# STM32N657xx register map
File version: 1.0
Registers are 32-bit, read-write, reset 0x0 unless marked. A register's access mark holds for its fields unless they carry their own. Offsets are from the block's base; [hi:lo] are bit positions; {n}, {i} and the like mark numbered series; 'fields as' and 'values as' point back to an identical list.

## RCC (part 1 of 2) — Reset and Clock Control
Base 0x46028000
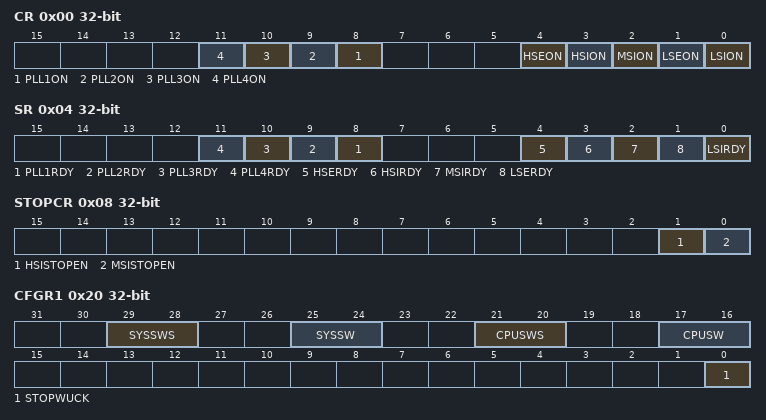
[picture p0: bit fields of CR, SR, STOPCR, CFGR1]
0x00 CR — RCC control register
  [n+7] PLL{n}ON (n=1..4) — PLL{n} enable
  [4] HSEON — HSE oscillator enable
  [3] HSION — HSI oscillator enable
  [2] MSION — MSI oscillator enable
  [1] LSEON — LSE oscillator enable
  [0] LSION — LSI oscillator enable
0x04 SR — RCC status register
  [n+7] PLL{n}RDY (n=1..4) — PLL{n} clock ready flag
  [4] HSERDY — HSE clock ready flag
  [3] HSIRDY — HSI clock ready flag
  [2] MSIRDY — MSI clock ready flag
  [1] LSERDY — LSE clock ready flag
  [0] LSIRDY — LSI clock ready flag
0x08 STOPCR — RCC Stop mode control register
  [1] HSISTOPEN — HSI oscillator enable
  [0] MSISTOPEN — MSI oscillator enable
0x20 CFGR1 — RCC configuration register 1
  [29:28] SYSSWS — System clock switch status
    0=HSI (HSI used as system bus clocks); 1=MSI (MSI used as system bus clocks); 2=HSE (HSE used as system bus clocks); 3=IC2_IC6_IC11 (IC2/IC6/IC11 used as system bus clocks)
  [25:24] SYSSW — System clock switch selection
    0=HSI (Select HSI as system bus clocks); 1=MSI (Select MSI as system bus clocks); 2=HSE (Select HSE as system bus clocks); 3=IC2_IC6_IC11 (Select IC2/IC6/IC11 as system bus clocks)
  [21:20] CPUSWS — CPU clock switch status
    0=HSI (HSI used as CPU clock); 1=MSI (MSI used as CPU clock); 2=HSE (HSE used as CPU clock); 3=IC1 (IC1 used as CPU clock)
  [17:16] CPUSW — CPU clock switch selection
    0=HSI (Select HSI as CPU clock); 1=MSI (Select MSI as CPU clock); 2=HSE (Select HSE as CPU clock); 3=IC1 (Select IC1 as CPU clock)
  [0] STOPWUCK — System clock selection after a wake up from system stop
    0=HSI; 1=MSI
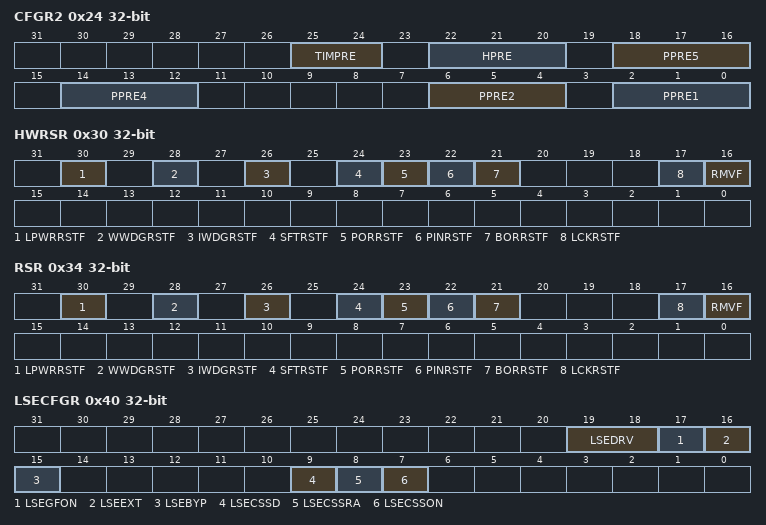
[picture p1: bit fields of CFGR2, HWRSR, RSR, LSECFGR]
0x24 CFGR2 — RCC configuration register 2
  [25:24] TIMPRE — Timer clock prescaler selection
  [22:20] HPRE — AHB clock prescaler
    0=DIV_1; 1=DIV_2; 2=DIV_4; 3=DIV_8; 4=DIV_16; 5=DIV_32; 6=DIV_64; 7=DIV_128
  [18:16] PPRE5 — CPU domain APB5 prescaler
    values as HPRE
  [14:12] PPRE4 — CPU domain APB4 prescaler
    values as HPRE
  [6:4] PPRE2 — CPU domain APB2 prescaler
    values as HPRE
  [2:0] PPRE1 — CPU domain APB1 prescaler
    values as HPRE
0x2C BDCR — RCC backup domain protection register
  [31] VSWRST — Vswitch (VSW) domain software reset
0x30 HWRSR — RCC reset status register for hardware
  [30] LPWRRSTF — Illegal Stop or Standby flag
  [28] WWDGRSTF — Window watchdog reset flag
  [26] IWDGRSTF — Independent watchdog reset flag
  [24] SFTRSTF — Software system reset flag
  [23] PORRSTF — POR/PDR reset flag
  [22] PINRSTF — Pin reset flag (NRST)
  [21] BORRSTF — BOR reset flag
  [17] LCKRSTF — CPU lockup reset flag
  [16] RMVF — Remove reset flag
0x34 RSR — RCC reset register
  fields as HWRSR
0x40 LSECFGR — RCC LSE configuration register
  [19:18] LSEDRV — LSE oscillator driving capability
    0=LOW; 2=MEDIUMLOW; 1=MEDIUMHIGH; 3=HIGH
  [17] LSEGFON — LSE clock glitch filter enable
  [16] LSEEXT — LSE clock type in bypass mode
  [15] LSEBYP — LSE clock bypass
  [9] LSECSSD — LSE clock security system (CSS) failure detection
  [8] LSECSSRA — LSE clock security system (CSS) rearm function
  [7] LSECSSON — LSE clock security system (CSS) enable
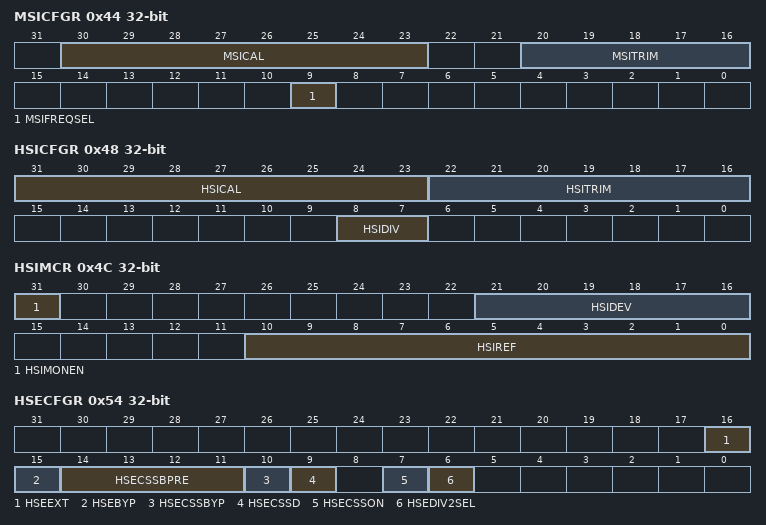
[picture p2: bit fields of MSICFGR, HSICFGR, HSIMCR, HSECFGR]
0x44 MSICFGR — RCC MSI configuration register
  [30:23] MSICAL — MSI clock calibration
  [20:16] MSITRIM — MSI clock trimming
  [9] MSIFREQSEL — MSI oscillator frequency selection
    0=FREQ_4MHZ; 1=FREQ_16MHZ
0x48 HSICFGR — RCC HSI configuration register
  [31:23] HSICAL — HSI clock calibration
  [22:16] HSITRIM — HSI clock trimming
  [8:7] HSIDIV — HSI clock divider
    0=DIV_1; 1=DIV_2; 2=DIV_4; 3=DIV_8
0x4C HSIMCR — RCC HSI Monitor control register
  [31] HSIMONEN — HSI clock period monitor enable
  [21:16] HSIDEV — HSI clock count deviation value
  [10:0] HSIREF — HSI clock-cycle counter reference value
0x50 HSIMSR — RCC HSI Monitor status register
  [10:0] HSIVAL — HSI clock-cycle counter measured value
0x54 HSECFGR — RCC HSE configuration register
  [16] HSEEXT — HSE clock type in bypass mode
  [15] HSEBYP — HSE clock bypass
  [14:11] HSECSSBPRE — HSE CSS bypass divider
  [10] HSECSSBYP — HSE CSS bypass enable
  [9] HSECSSD — HSE CSS failure detection
  [7] HSECSSON — HSE CSS enable
  [6] HSEDIV2SEL — HSE div2 clock source select
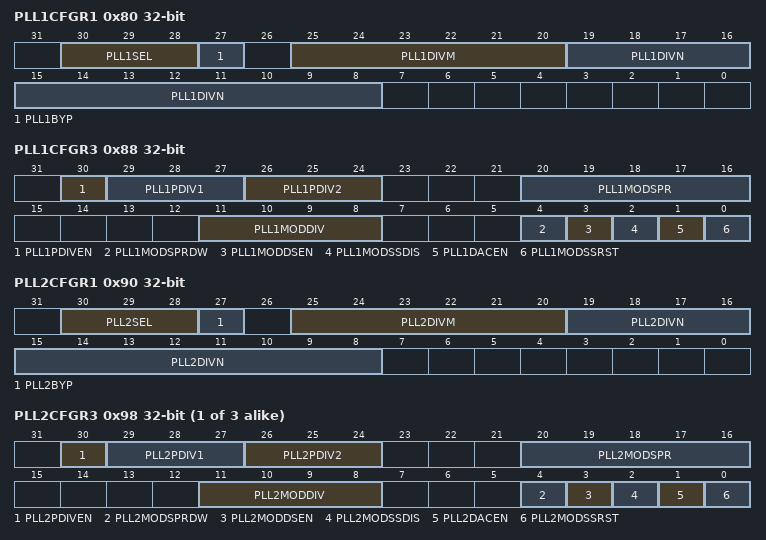
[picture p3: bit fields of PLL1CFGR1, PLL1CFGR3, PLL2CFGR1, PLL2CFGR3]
0x80 PLL1CFGR1 — RCC PLL1 configuration register 1
  [30:28] PLL1SEL — PLL1 source selection of the reference clock
    0=HSI; 1=MSI; 2=HSE; 3=I2S_CKIN
  [27] PLL1BYP — PLL1 bypass
  [25:20] PLL1DIVM — PLL1 reference input clock divide frequency ratio
  [19:8] PLL1DIVN — PLL1 integer part for the VCO multiplication factor
{0x74+0x10*i} PLL{i}CFGR2 (i=1..4) — RCC PLL{i} configuration register 2
  [23:0] PLL{i}DIVNFRAC — PLL{i} fractional part of the VCO multiplication factor
0x88 PLL1CFGR3 — RCC PLL1 configuration register 3
  [30] PLL1PDIVEN — PLL1 post divider POSTDIV1, POSTDIV2, and PLL clock output enable
  [29:27] PLL1PDIV1 — PLL1 VCO frequency divider level 1
  [26:24] PLL1PDIV2 — PLL1 VCO frequency divider level 2
  [20:16] PLL1MODSPR — PLL1 modulation spread depth adjustment
  [11:8] PLL1MODDIV — PLL1 modulation division frequency adjustment
  [4] PLL1MODSPRDW — PLL1 modulation spread spectrum down
  [3] PLL1MODDSEN — PLL1 modulation spread spectrum (and fractional divide) enable
  [2] PLL1MODSSDIS — PLL1 modulation spread spectrum disable
  [1] PLL1DACEN — PLL1 noise canceling DAC enable in fractional mode
  [0] PLL1MODSSRST — PLL1 modulation spread spectrum reset
0x90 PLL2CFGR1 — RCC PLL2 configuration register 1
  [30:28] PLL2SEL — PLL2 source selection of the reference clock
    0=HSI; 1=MSI; 2=HSE; 3=I2S_CKIN
  [27] PLL2BYP — PLL2 bypass
  [25:20] PLL2DIVM — PLL2 reference input clock divide frequency ratio
  [19:8] PLL2DIVN — PLL2 integer part for the VCO multiplication factor
{0x78+0x10*i} PLL{i}CFGR3 (i=2..4) — RCC PLL{i} configuration register 3
  [30] PLL{i}PDIVEN — PLL{i} post divider POSTDIV1, POSTDIV2, and PLL clock output enable
  [29:27] PLL{i}PDIV1 — PLL{i} VCO frequency divider level 1
  [26:24] PLL{i}PDIV2 — PLL{i} VCO frequency divider level 2
  [20:16] PLL{i}MODSPR — PLL{i} modulation spread depth adjustment
  [11:8] PLL{i}MODDIV — PLL{i} modulation division frequency adjustment
  [4] PLL{i}MODSPRDW — PLL{i} modulation down spread
  [3] PLL{i}MODDSEN — PLL{i} modulation spread spectrum (and fractional divide) enable
  [2] PLL{i}MODSSDIS — PLL{i} modulation spread spectrum disable
  [1] PLL{i}DACEN — PLL{i} noise canceling DAC enable in fractional mode
  [0] PLL{i}MODSSRST — PLL{i} modulation spread spectrum reset
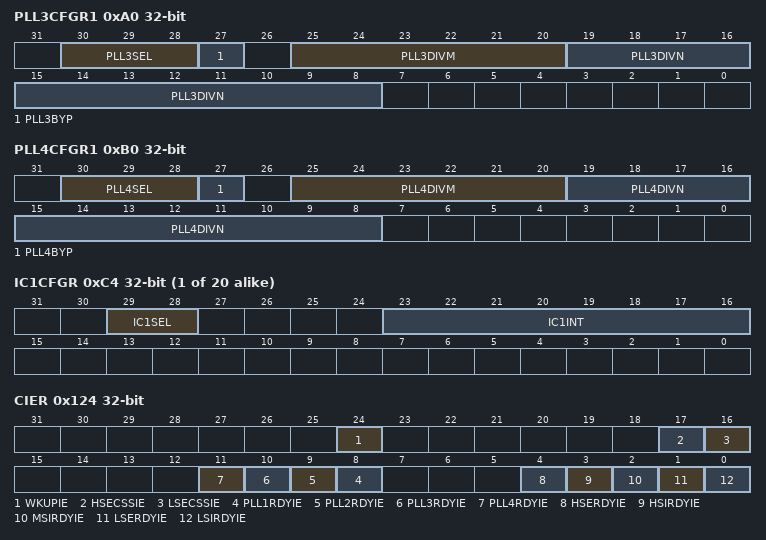
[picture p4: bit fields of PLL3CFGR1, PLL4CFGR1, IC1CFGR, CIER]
0xA0 PLL3CFGR1 — RCC PLL3 configuration register 1
  [30:28] PLL3SEL — PLL3 source selection of the reference clock
    0=HSI; 1=MSI; 2=HSE; 3=I2S_CKIN
  [27] PLL3BYP — PLL3 bypass
  [25:20] PLL3DIVM — PLL3 reference input clock divide frequency ratio
  [19:8] PLL3DIVN — PLL3 Integer part for the VCO multiplication factor
0xB0 PLL4CFGR1 — RCC PLL4 configuration register 1
  [30:28] PLL4SEL — PLL4 source selection of the reference clock
    0=HSI; 1=MSI; 2=HSE; 3=I2S_CKIN
  [27] PLL4BYP — PLL4 bypass
  [25:20] PLL4DIVM — PLL4 reference input clock divide frequency ratio
  [19:8] PLL4DIVN — PLL4 integer part for the VCO multiplication factor
{0xC0+4i} IC{i}CFGR (i=1..20) — RCC IC{i} configuration register
  [29:28] IC{i}SEL — Divider IC{i} source selection
    {v}=PLL{v+1} (v=0..3)
  [23:16] IC{i}INT — Divider IC{i} integer division factor
0x124 CIER — RCC clock-source interrupt enable register
  [24] WKUPIE — CPU wake-up from Stop interrupt enable
  [17] HSECSSIE — HSE CSS interrupt enable
  [16] LSECSSIE — LSE CSS interrupt enable
  [n+7] PLL{n}RDYIE (n=1..4) — PLL{n} ready interrupt enable
  [4] HSERDYIE — HSE ready interrupt enable
  [3] HSIRDYIE — HSI ready interrupt enable
  [2] MSIRDYIE — MSI ready interrupt enable
  [1] LSERDYIE — LSE ready interrupt enable
  [0] LSIRDYIE — LSI ready interrupt enable
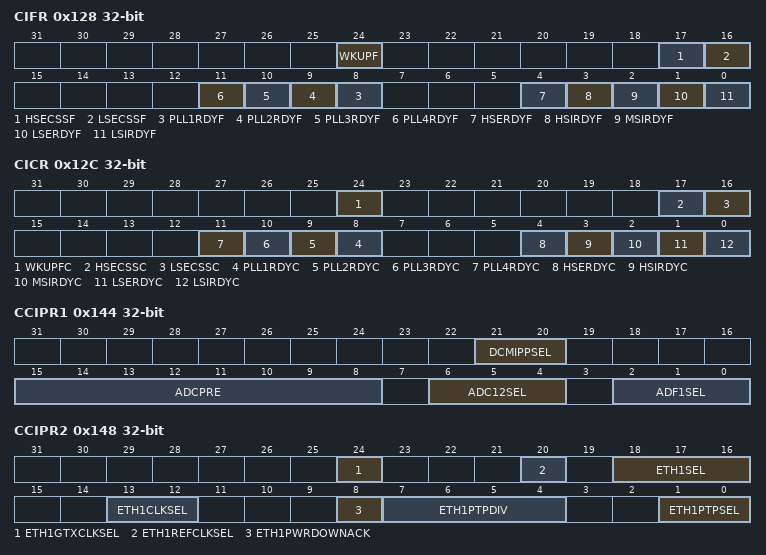
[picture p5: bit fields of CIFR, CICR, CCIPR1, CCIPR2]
0x128 CIFR — RCC clock-source interrupt flag register
  [24] WKUPF — CPU wake-up from Stop interrupt flag
  [17] HSECSSF — HSE ready interrupt flag
  [16] LSECSSF — LSE ready interrupt flag
  [n+7] PLL{n}RDYF (n=1..4) — PLL{n} ready interrupt flag
  [4] HSERDYF — HSE ready interrupt flag
  [3] HSIRDYF — HSI ready interrupt flag
  [2] MSIRDYF — MSI ready interrupt flag
  [1] LSERDYF — LSE ready interrupt flag
  [0] LSIRDYF — LSI ready interrupt flag
0x12C CICR — RCC clock-source interrupt clear register
  [24] WKUPFC — CPU wake-up ready interrupt clear
  [17] HSECSSC — HSE ready interrupt clear
  [16] LSECSSC — LSE ready interrupt clear
  [n+7] PLL{n}RDYC (n=1..4) — PLL{n} ready interrupt clear
  [4] HSERDYC — HSE ready interrupt clear
  [3] HSIRDYC — HSI ready interrupt clear
  [2] MSIRDYC — MSI ready interrupt clear
  [1] LSERDYC — LSE ready interrupt clear
  [0] LSIRDYC — LSI ready interrupt clear
0x144 CCIPR1 — RCC clock configuration for independent peripheral register 1
  [21:20] DCMIPPSEL — Source selection for the DCMIPP kernel clock
    0=PCLK5; 1=CLKP; 2=IC17; 3=HSI
  [15:8] ADCPRE — ADC12 Bus Slave clock divider selection (for clock ck_icn_s_vencram)
  [6:4] ADC12SEL — Source selection for the ADC12 kernel clock
    0=HCLK; 1=CLKP; 2=IC7; 3=IC8; 4=MSI; 5=HSI; 6=I2S_CKIN; 7=TIMG
  [2:0] ADF1SEL — Source selection for the ADF1 kernel clock
    values as ADC12SEL
0x148 CCIPR2 — RCC clock configuration for independent peripheral register 2
  [24] ETH1GTXCLKSEL — Set and reset by software
    0=EXT; 1=INT
  [20] ETH1REFCLKSEL — Set and reset by software
    0=EXT; 1=INT
  [18:16] ETH1SEL — Set and reset by software
    0=MII; 1=RGMII; 4=RMII; 7=IF
  [13:12] ETH1CLKSEL — Source selection for the ETH1 kernel clock
    0=HCLK; 1=CLKP; 2=IC12; 3=HSE
  [8] ETH1PWRDOWNACK — Set and reset by software
  [7:4] ETH1PTPDIV — ETH1 Kernel clock divider selection (for clock ck_ker_eth1ptp)
    {v}=DIV_{v+1} (v=0..15)
  [1:0] ETH1PTPSEL — Source selection for the ETH1 kernel clock
    0=HCLK; 1=CLKP; 2=IC13; 3=HSE
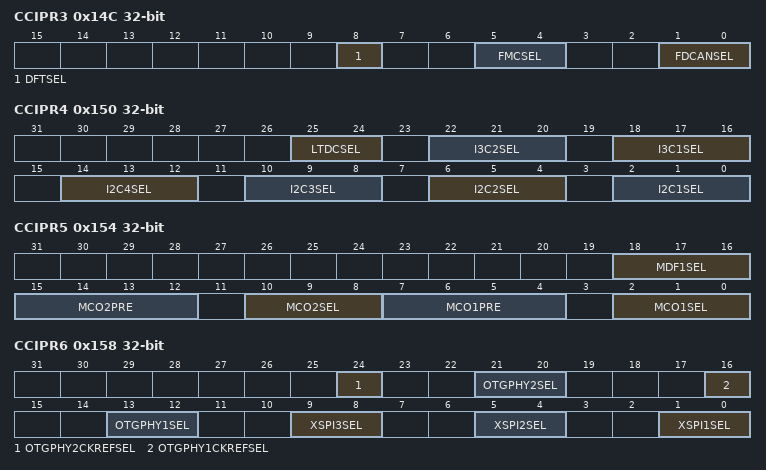
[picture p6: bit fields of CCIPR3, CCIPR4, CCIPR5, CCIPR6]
0x14C CCIPR3 — RCC clock configuration for independent peripheral register 3
  [8] DFTSEL — Source selection for the DFT kernel clock
  [5:4] FMCSEL — Source selection for the FMC kernel clock
    0=HCLK; 1=CLKP; 2=IC3; 3=IC4
  [1:0] FDCANSEL — Source selection for the FDCAN kernel clock
    0=PCLK1; 1=CLKP; 2=IC19; 3=HSE
0x150 CCIPR4 — RCC clock configuration for independent peripheral register 4
  [25:24] LTDCSEL — Source selection for the LTDC kernel clock
    0=PCLK5; 1=CLKP; 2=IC16; 3=HSI
  [22:20] I3C2SEL — Source selection for the I3C2 kernel clock
  [18:16] I3C1SEL — Source selection for the I3C1 kernel clock
  [4n-2:4n-4] I2C{n}SEL (n=1..4) — Source selection for the I2C{n} kernel clock
0x154 CCIPR5 — RCC clock configuration for independent peripheral register 5
  [18:16] MDF1SEL — Source selection for the MDF1 kernel clock
    values as CCIPR1.ADC12SEL
  [15:12] MCO2PRE — MCO2 Kernel clock divider selection (for clock MCO2)
  [10:8] MCO2SEL — Source selection for the MCO2 kernel clock
  [7:4] MCO1PRE — MCO1 Kernel clock divider selection (for clock MCO1)
  [2:0] MCO1SEL — Source selection for the MCO1 kernel clock
0x158 CCIPR6 — RCC clock configuration for independent peripheral register 6
  [24] OTGPHY2CKREFSEL — Set and reset by software
  [21:20] OTGPHY2SEL — Source selection for the OTGPHY2 kernel clock
  [16] OTGPHY1CKREFSEL — Set and reset by software
  [13:12] OTGPHY1SEL — Source selection for the OTGPHY1 kernel clock
  [9:8] XSPI3SEL — Source selection for the XSPI3 kernel clock
  [5:4] XSPI2SEL — Source selection for the XSPI2 kernel clock
  [1:0] XSPI1SEL — Source selection for the XSPI1 kernel clock
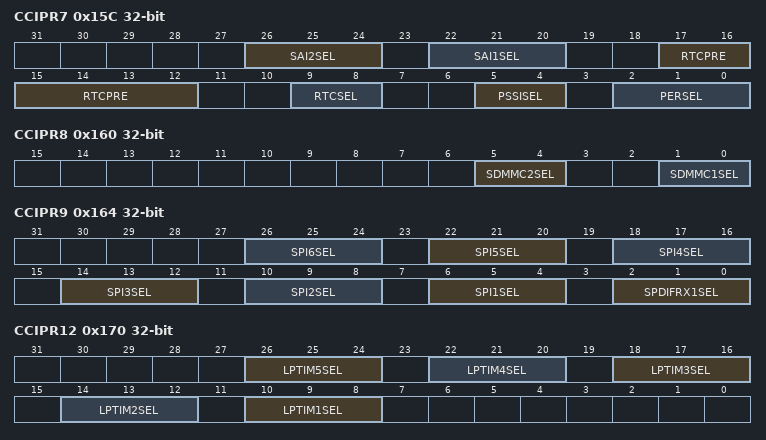
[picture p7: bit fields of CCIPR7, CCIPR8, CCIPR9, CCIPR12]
0x15C CCIPR7 — RCC clock configuration for independent peripheral register 7
  [26:24] SAI2SEL — Source selection for the SAI2 kernel clock
  [22:20] SAI1SEL — Source selection for the SAI1 kernel clock
  [17:12] RTCPRE — RTC OSC clock divider selection (for clock hse_ck)
    0=DIV_1; 1=DIV_4; 2=DIV_9; 3=DIV_16; 4=DIV_25; 5=DIV_36; 6=DIV_49; 7=DIV_64; 8=DIV_81; 9=DIV_100; 10=DIV_121; 11=DIV_144; 12=DIV_169; 13=DIV_196; 14=DIV_225; 15=DIV_256; 16=DIV_289; 17=DIV_324; 18=DIV_361; 19=DIV_400; 20=DIV_441; 21=DIV_484; 22=DIV_529; 23=DIV_576; 24=DIV_625; 25=DIV_676; 26=DIV_729; 27=DIV_784; 28=DIV_841; 29=DIV_900; 30=DIV_961; 31=DIV_1024; 32=DIV_1089; 33=DIV_1156; 34=DIV_1225; 35=DIV_1296; 36=DIV_1369; 37=DIV_1444; 38=DIV_1521; 39=DIV_1600; 40=DIV_1681; 41=DIV_1764; 42=DIV_1849; 43=DIV_1936; 44=DIV_2025; 45=DIV_2116; 46=DIV_2209; 47=DIV_2304; 48=DIV_2401; 49=DIV_2500; 50=DIV_2601; 51=DIV_2704; 52=DIV_2809; 53=DIV_2916; 54=DIV_3025; 55=DIV_3136; 56=DIV_3249; 57=DIV_3364; 58=DIV_3481; 59=DIV_3600; 60=DIV_3721; 61=DIV_3844; 62=DIV_3969; 63=DIV_4096
  [9:8] RTCSEL — Source selection for the RTC kernel clock
    0=NONE; 1=LSE; 2=LSI; 3=HSE
  [5:4] PSSISEL — Source selection for the PSSI kernel clock
    0=HCLK; 1=CLKP; 2=IC20; 3=HSI
  [2:0] PERSEL — Source selection for the PER kernel clock
    0=HSI; 1=MSI; 2=HSE; 3=IC19; 4=IC5; 5=IC10; 6=IC15; 7=IC20
0x160 CCIPR8 — RCC clock configuration for independent peripheral register 8
  [5:4] SDMMC2SEL — Source selection for the SDMMC2 kernel clock
  [1:0] SDMMC1SEL — Source selection for the SDMMC1 kernel clock
0x164 CCIPR9 — RCC clock configuration for independent peripheral register 9
  [4n+2:4n] SPI{n}SEL (n=1..6) — Source selection for the SPI{n} kernel clock
  [2:0] SPDIFRX1SEL — Source selection for the SPDIFRX1 kernel clock
    0=PCLK1; 1=CLKP; 2=IC7; 3=IC8; 4=MSI; 5=HSI; 6=I2S_CKIN; 7=CLKSOURCE
0x170 CCIPR12 — RCC clock configuration for independent peripheral register 12
  [4n+6:4n+4] LPTIM{n}SEL (n=1..5) — Source selection for the LPTIM{n} kernel clock
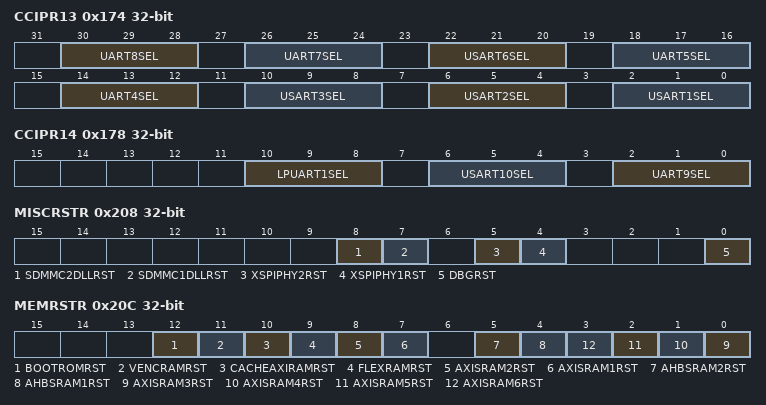
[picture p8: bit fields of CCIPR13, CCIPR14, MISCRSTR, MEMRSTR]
0x174 CCIPR13 — RCC clock configuration for independent peripheral register 13
  [30:28] UART8SEL — Source selection for the UART8 kernel clock
  [26:24] UART7SEL — Source selection for the UART7 kernel clock
  [22:20] USART6SEL — Source selection for the USART6 kernel clock
  [18:16] UART5SEL — Source selection for the UART5 kernel clock
  [14:12] UART4SEL — Source selection for the UART4 kernel clock
  [10:8] USART3SEL — Source selection for the USART3 kernel clock
  [6:4] USART2SEL — Source selection for the USART2 kernel clock
  [2:0] USART1SEL — Source selection for the USART1 kernel clock
0x178 CCIPR14 — RCC clock configuration for independent peripheral register 14
  [10:8] LPUART1SEL — Source selection for the LPUART1 kernel clock
    0=PCLK4; 1=CLKP; 2=IC9; 3=IC14; 4=LSE; 5=MSI; 6=HSI; 7=CLKSOURCE
  [6:4] USART10SEL — Source selection for the USART10 kernel clock
  [2:0] UART9SEL — Source selection for the UART9 kernel clock
0x208 MISCRSTR — RCC miscellaneous configurations reset register
  [8] SDMMC2DLLRST — SDMMC2DLL reset
  [7] SDMMC1DLLRST — SDMMC1DLL reset
  [5] XSPIPHY2RST — XSPIPHY2 reset
  [4] XSPIPHY1RST — XSPIPHY1 reset
  [0] DBGRST — DBG reset
0x20C MEMRSTR — RCC embedded memories reset register
  [12] BOOTROMRST — Boot ROM reset
  [11] VENCRAMRST — VENCRAM reset
  [10] CACHEAXIRAMRST — CACHEAXIRAM reset
  [9] FLEXRAMRST — FLEXRAM reset
  [8] AXISRAM2RST — AXISRAM2 reset
  [7] AXISRAM1RST — AXISRAM1 reset
  [5] AHBSRAM2RST — AHBSRAM2 reset
  [4] AHBSRAM1RST — AHBSRAM1 reset
  [n-3] AXISRAM{n}RST (n=3..6) — AXISRAM{n} reset
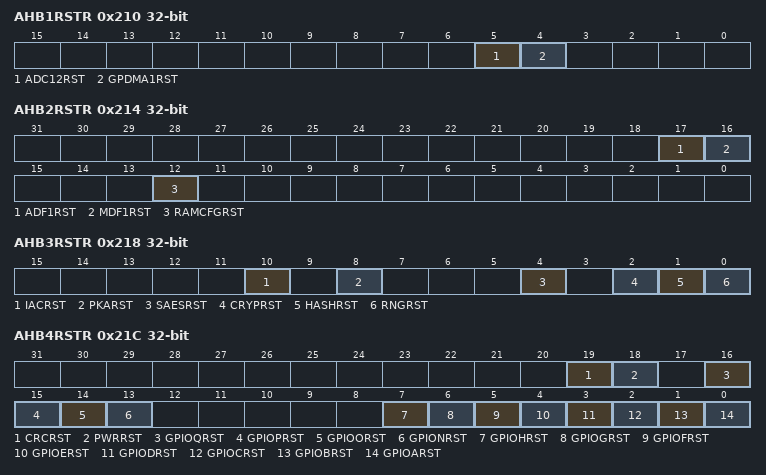
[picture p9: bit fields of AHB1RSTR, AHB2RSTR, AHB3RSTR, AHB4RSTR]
0x210 AHB1RSTR — RCC AHB1 reset register
  [5] ADC12RST — ADC12 reset
  [4] GPDMA1RST — GPDMA1 reset
0x214 AHB2RSTR — RCC AHB2 reset register
  [17] ADF1RST — ADF1 reset
  [16] MDF1RST — MDF1 reset
  [12] RAMCFGRST — RAMCFG reset
0x218 AHB3RSTR — RCC AHB3 reset register
  [10] IACRST — IAC reset
  [8] PKARST — PKA reset
  [4] SAESRST — SAES reset
  [2] CRYPRST — CRYP reset
  [1] HASHRST — HASH reset
  [0] RNGRST — RNG reset
0x21C AHB4RSTR — RCC AHB4 reset register
  [19] CRCRST — CRC reset
  [18] PWRRST — PWR reset
  [16] GPIOQRST — GPIO Q reset
  [15] GPIOPRST — GPIO P reset
  [14] GPIOORST — GPIO O reset
  [13] GPIONRST — GPIO N reset
  [7] GPIOHRST — GPIO H reset
  [6] GPIOGRST — GPIO G reset
  [5] GPIOFRST — GPIO F reset
  [4] GPIOERST — GPIO E reset
  [3] GPIODRST — GPIO D reset
  [2] GPIOCRST — GPIO C reset
  [1] GPIOBRST — GPIO B reset
  [0] GPIOARST — GPIO A reset
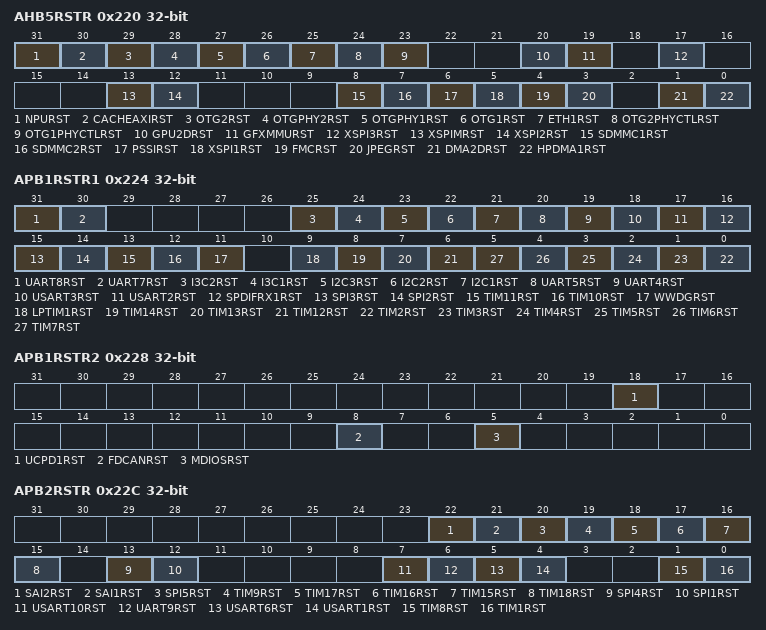
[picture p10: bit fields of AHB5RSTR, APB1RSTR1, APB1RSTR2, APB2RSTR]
0x220 AHB5RSTR — RCC AHB5 reset register
  [31] NPURST — NPU reset
  [30] CACHEAXIRST — CACHEAXI reset
  [29] OTG2RST — OTG2 reset
  [28] OTGPHY2RST — OTGPHY2 reset
  [27] OTGPHY1RST — OTGPHY1 reset
  [26] OTG1RST — OTG1 reset
  [25] ETH1RST — ETH1 reset
  [24] OTG2PHYCTLRST — OTG2PHYCTL reset
  [23] OTG1PHYCTLRST — OTG1PHYCTL reset
  [20] GPU2DRST — GPU2D reset
  [19] GFXMMURST — GFXMMU reset
  [17] XSPI3RST — XSPI3 reset
  [13] XSPIMRST — XSPIM reset
  [12] XSPI2RST — XSPI2 reset
  [8] SDMMC1RST — SDMMC1 reset
  [7] SDMMC2RST — SDMMC2 reset
  [6] PSSIRST — PSSI reset
  [5] XSPI1RST — XSPI1 reset
  [4] FMCRST — FMC reset
  [3] JPEGRST — JPEG reset
  [1] DMA2DRST — DMA2D reset
  [0] HPDMA1RST — HPDMA1 reset
0x224 APB1RSTR1 — RCC APB1 reset register 1
  [31] UART8RST — UART8 reset
  [30] UART7RST — UART7 reset
  [25] I3C2RST — I3C2 reset
  [24] I3C1RST — I3C1 reset
  [23] I2C3RST — I2C3 reset
  [22] I2C2RST — I2C2 reset
  [21] I2C1RST — I2C1 reset
  [20] UART5RST — UART5 reset
  [19] UART4RST — UART4 reset
  [18] USART3RST — USART3 reset
  [17] USART2RST — USART2 reset
  [16] SPDIFRX1RST — SPDIFRX1 reset
  [15] SPI3RST — SPI3 reset
  [14] SPI2RST — SPI2 reset
  [13] TIM11RST — TIM11 reset
  [12] TIM10RST — TIM10 reset
  [11] WWDGRST — WWDG reset
  [9] LPTIM1RST — LPTIM1 reset
  [8] TIM14RST — TIM14 reset
  [7] TIM13RST — TIM13 reset
  [6] TIM12RST — TIM12 reset
  [n-2] TIM{n}RST (n=2..7) — TIM{n} reset
0x228 APB1RSTR2 — RCC APB1 reset register 2
  [18] UCPD1RST — UCPD1 reset
  [8] FDCANRST — FDCAN reset
  [5] MDIOSRST — MDIOS reset
0x22C APB2RSTR — RCC APB2 reset register
  [22] SAI2RST — SAI2 reset
  [21] SAI1RST — SAI1 reset
  [20] SPI5RST — SPI5 reset
  [19] TIM9RST — TIM9 reset
  [18] TIM17RST — TIM17 reset
  [17] TIM16RST — TIM16 reset
  [16] TIM15RST — TIM15 reset
  [15] TIM18RST — TIM18 reset
  [13] SPI4RST — SPI4 reset
  [12] SPI1RST — SPI1 reset
  [7] USART10RST — USART10 reset
  [6] UART9RST — UART9 reset
  [5] USART6RST — USART6 reset
  [4] USART1RST — USART1 reset
  [1] TIM8RST — TIM8 reset
  [0] TIM1RST — TIM1 reset
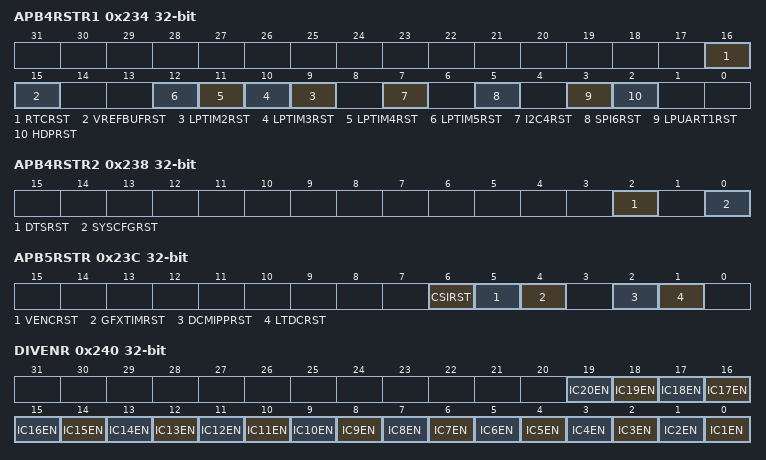
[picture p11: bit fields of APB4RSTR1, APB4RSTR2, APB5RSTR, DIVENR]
0x234 APB4RSTR1 — RCC APB4 reset register 1
  [16] RTCRST — RTC reset
  [15] VREFBUFRST — VREFBUF reset
  [n+7] LPTIM{n}RST (n=2..5) — LPTIM{n} reset
  [7] I2C4RST — I2C4 reset
  [5] SPI6RST — SPI6 reset
  [3] LPUART1RST — LPUART1 reset
  [2] HDPRST — HDP reset
0x238 APB4RSTR2 — RCC APB4 reset register 2
  [2] DTSRST — DTS reset
  [0] SYSCFGRST — SYSCFG reset
0x23C APB5RSTR — RCC APB5 reset register
  [6] CSIRST — CSI reset
  [5] VENCRST — VENC reset
  [4] GFXTIMRST — GFXTIM reset
  [2] DCMIPPRST — DCMIPP reset
  [1] LTDCRST — LTDC reset
0x240 DIVENR — RCC IC dividers enable register
  [n-1] IC{n}EN (n=1..20) — IC{n} enable
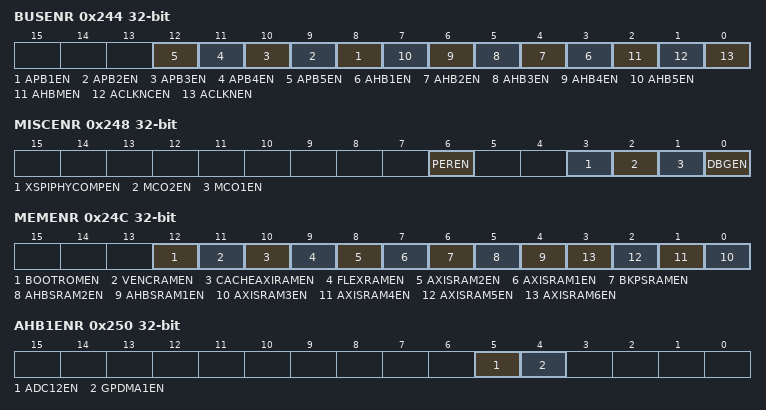
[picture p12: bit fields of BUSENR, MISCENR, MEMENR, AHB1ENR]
0x244 BUSENR — RCC embedded buses enable register
  [n+7] APB{n}EN (n=1..5) — APB{n} enable
  [n+2] AHB{n}EN (n=1..5) — AHB{n} enable
  [2] AHBMEN — AHBM enable
  [1] ACLKNCEN — ACLKNC enable
  [0] ACLKNEN — ACLKN enable
0x248 MISCENR — RCC miscellaneous configurations enable register
  [6] PEREN — PER enable
  [3] XSPIPHYCOMPEN — XSPIPHYCOMP enable
  [2] MCO2EN — MCO2 enable
  [1] MCO1EN — MCO1 enable
  [0] DBGEN — DBG enable
0x24C MEMENR — RCC embedded memories enable register
  [12] BOOTROMEN — Boot ROM enable
  [11] VENCRAMEN — VENCRAM enable
  [10] CACHEAXIRAMEN — CACHEAXIRAM enable
  [9] FLEXRAMEN — FLEXRAM enable
  [8] AXISRAM2EN — AXISRAM2 enable
  [7] AXISRAM1EN — AXISRAM1 enable
  [6] BKPSRAMEN — BKPSRAM enable
  [5] AHBSRAM2EN — AHBSRAM2 enable
  [4] AHBSRAM1EN — AHBSRAM1 enable
  [n-3] AXISRAM{n}EN (n=3..6) — AXISRAM{n} enable
0x250 AHB1ENR — RCC AHB1 enable register
  [5] ADC12EN — ADC12 enable
  [4] GPDMA1EN — GPDMA1 enable
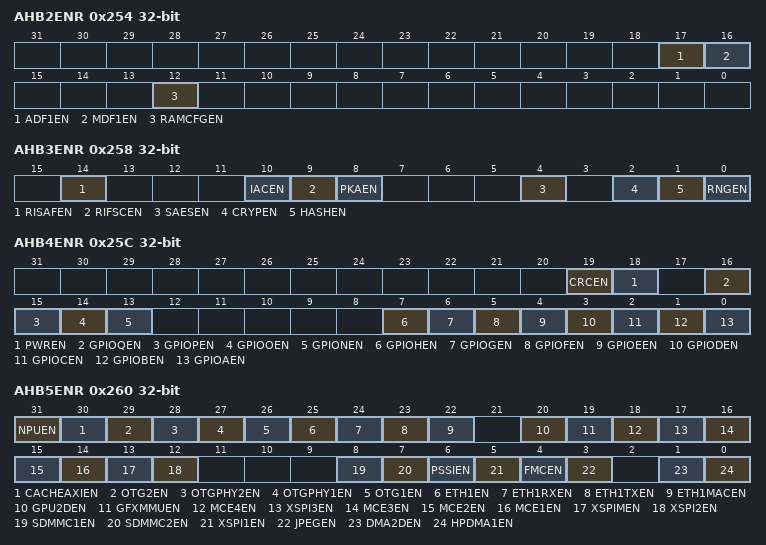
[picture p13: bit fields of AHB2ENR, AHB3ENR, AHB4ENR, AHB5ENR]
0x254 AHB2ENR — RCC AHB2 enable register
  [17] ADF1EN — ADF1 enable
  [16] MDF1EN — MDF1 enable
  [12] RAMCFGEN — RAMCFG enable
0x258 AHB3ENR — RCC AHB3 enable register
  [14] RISAFEN — RISAF enable
  [10] IACEN — IAC enable
  [9] RIFSCEN — RIFSC enable
  [8] PKAEN — PKA enable
  [4] SAESEN — SAES enable
  [2] CRYPEN — CRYP enable
  [1] HASHEN — HASH enable
  [0] RNGEN — RNG enable
0x25C AHB4ENR — RCC AHB4 enable register
  [19] CRCEN — CRC enable
  [18] PWREN — PWR enable
  [16] GPIOQEN — GPIO Q enable
  [15] GPIOPEN — GPIO P enable
  [14] GPIOOEN — GPIO O enable
  [13] GPIONEN — GPIO N enable
  [7] GPIOHEN — GPIO H enable
  [6] GPIOGEN — GPIO G enable
  [5] GPIOFEN — GPIO F enable
  [4] GPIOEEN — GPIO E enable
  [3] GPIODEN — GPIO D enable
  [2] GPIOCEN — GPIO C enable
  [1] GPIOBEN — GPIO B enable
  [0] GPIOAEN — GPIO A enable
0x260 AHB5ENR — RCC AHB5 enable register
  [31] NPUEN — NPU enable
  [30] CACHEAXIEN — CACHEAXI enable
  [29] OTG2EN — OTG2 enable
  [28] OTGPHY2EN — OTGPHY2 enable
  [27] OTGPHY1EN — OTGPHY1 enable
  [26] OTG1EN — OTG1 enable
  [25] ETH1EN — ETH1 enable
  [24] ETH1RXEN — ETH1RX enable
  [23] ETH1TXEN — ETH1TX enable
  [22] ETH1MACEN — ETH1MAC enable
  [20] GPU2DEN — GPU2D enable
  [19] GFXMMUEN — GFXMMU enable
  [18] MCE4EN — MCE4 enable
  [17] XSPI3EN — XSPI3 enable
  [16] MCE3EN — MCE3 enable
  [15] MCE2EN — MCE2 enable
  [14] MCE1EN — MCE1 enable
  [13] XSPIMEN — XSPIM enable
  [12] XSPI2EN — XSPI2 enable
  [8] SDMMC1EN — SDMMC1 enable
  [7] SDMMC2EN — SDMMC2 enable
  [6] PSSIEN — PSSI enable
  [5] XSPI1EN — XSPI1 enable
  [4] FMCEN — FMC enable
  [3] JPEGEN — JPEG enable
  [1] DMA2DEN — DMA2D enable
  [0] HPDMA1EN — HPDMA1 enable
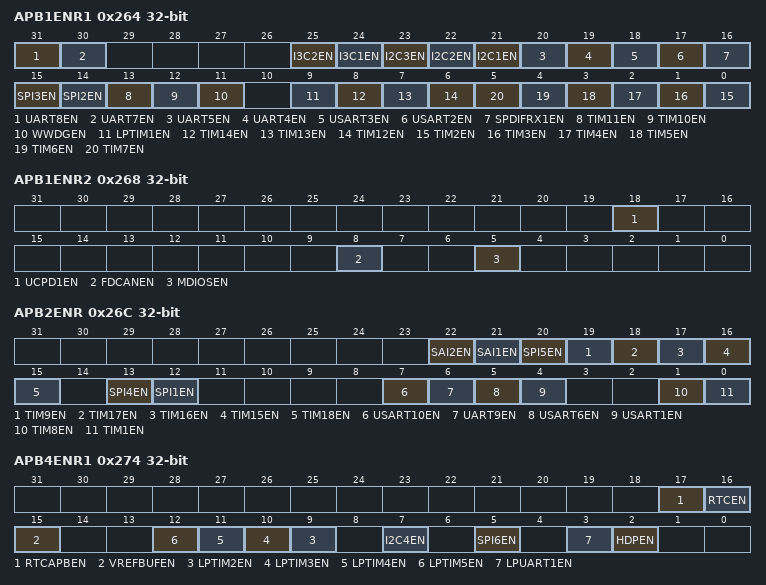
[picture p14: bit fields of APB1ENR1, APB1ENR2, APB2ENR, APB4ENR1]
0x264 APB1ENR1 — RCC APB1 enable register 1
  [31] UART8EN — UART8 enable
  [30] UART7EN — UART7 enable
  [25] I3C2EN — I3C2 enable
  [24] I3C1EN — I3C1 enable
  [23] I2C3EN — I2C3 enable
  [22] I2C2EN — I2C2 enable
  [21] I2C1EN — I2C1 enable
  [20] UART5EN — UART5 enable
  [19] UART4EN — UART4 enable
  [18] USART3EN — USART3 enable
  [17] USART2EN — USART2 enable
  [16] SPDIFRX1EN — SPDIFRX1 enable
  [15] SPI3EN — SPI3 enable
  [14] SPI2EN — SPI2 enable
  [13] TIM11EN — TIM11 enable
  [12] TIM10EN — TIM10 enable
  [11] WWDGEN — WWDG enable
  [9] LPTIM1EN — LPTIM1 enable
  [8] TIM14EN — TIM14 enable
  [7] TIM13EN — TIM13 enable
  [6] TIM12EN — TIM12 enable
  [n-2] TIM{n}EN (n=2..7) — TIM{n} enable
0x268 APB1ENR2 — RCC APB1 enable register 2
  [18] UCPD1EN — UCPD1 enable
  [8] FDCANEN — FDCAN enable
  [5] MDIOSEN — MDIOS enable
0x26C APB2ENR — RCC APB2 enable register
  [22] SAI2EN — SAI2 enable
  [21] SAI1EN — SAI1 enable
  [20] SPI5EN — SPI5 enable
  [19] TIM9EN — TIM9 enable
  [18] TIM17EN — TIM17 enable
  [17] TIM16EN — TIM16 enable
  [16] TIM15EN — TIM15 enable
  [15] TIM18EN — TIM18 enable
  [13] SPI4EN — SPI4 enable
  [12] SPI1EN — SPI1 enable
  [7] USART10EN — USART10 enable
  [6] UART9EN — UART9 enable
  [5] USART6EN — USART6 enable
  [4] USART1EN — USART1 enable
  [1] TIM8EN — TIM8 enable
  [0] TIM1EN — TIM1 enable
0x270 APB3ENR — RCC APB3 enable register
  [2] DFTEN — DFT enable
0x274 APB4ENR1 — RCC APB4 enable register 1
  [17] RTCAPBEN — RTCAPB enable
  [16] RTCEN — RTC enable
  [15] VREFBUFEN — VREFBUF enable
  [n+7] LPTIM{n}EN (n=2..5) — LPTIM{n} enable
  [7] I2C4EN — I2C4 enable
  [5] SPI6EN — SPI6 enable
  [3] LPUART1EN — LPUART1 enable
  [2] HDPEN — HDP enable
0x278 APB4ENR2 — RCC APB4 enable register 2
  [2] DTSEN — DTS enable
  [1] BSECEN — BSEC enable
  [0] SYSCFGEN — SYSCFG enable
0x27C APB5ENR — RCC APB5 enable register
  [6] CSIEN — CSI enable
  [5] VENCEN — VENC enable
  [4] GFXTIMEN — GFXTIM enable
  [2] DCMIPPEN — DCMIPP enable
  [1] LTDCEN — LTDC enable
0x284 BUSLPENR — RCC embedded buses sleep enable register
  [1] ACLKNCLPEN — ACLKNC enable
  [0] ACLKNLPEN — ACLKN enable
0x288 MISCLPENR — RCC miscellaneous configurations sleep enable register
  [6] PERLPEN — PER enable
  [3] XSPIPHYCOMPLPEN — XSPIPHYCOMP enable
  [0] DBGLPEN — DBG enable
0x28C MEMLPENR — RCC embedded memories sleep enable register
  [12] BOOTROMLPEN — Boot ROM enable
  [11] VENCRAMLPEN — VENCRAM enable
  [10] CACHEAXIRAMLPEN — CACHEAXIRAM enable
  [9] FLEXRAMLPEN — FLEXRAM enable
  [8] AXISRAM2LPEN — AXISRAM2 enable
  [7] AXISRAM1LPEN — AXISRAM1 enable
  [6] BKPSRAMLPEN — BKPSRAM enable
  [5] AHBSRAM2LPEN — AHBSRAM2 enable
  [4] AHBSRAM1LPEN — AHBSRAM1 enable
  [n-3] AXISRAM{n}LPEN (n=3..6) — AXISRAM{n} enable
0x290 AHB1LPENR — RCC AHB1 sleep enable register
  [5] ADC12LPEN — ADC12 enable
  [4] GPDMA1LPEN — GPDMA1 enable
0x294 AHB2LPENR — RCC AHB2 sleep enable register
  [17] ADF1LPEN — ADF1 enable
  [16] MDF1LPEN — MDF1 enable
  [12] RAMCFGLPEN — RAMCFG enable
0x298 AHB3LPENR — RCC AHB3 sleep enable register
  [14] RISAFLPEN — RISAF enable
  [10] IACLPEN — IAC enable
  [9] RIFSCLPEN — RIFSC enable
  [8] PKALPEN — PKA enable
  [4] SAESLPEN — SAES enable
  [2] CRYPLPEN — CRYP enable
  [1] HASHLPEN — HASH enable
  [0] RNGLPEN — RNG enable
0x29C AHB4LPENR — RCC AHB4 sleep enable register
  [19] CRCLPEN — CRC enable
  [18] PWRLPEN — PWR enable
  [16] GPIOQLPEN — GPIO Q enable
  [15] GPIOPLPEN — GPIO P enable
  [14] GPIOOLPEN — GPIO O enable
  [13] GPIONLPEN — GPIO N enable
  [7] GPIOHLPEN — GPIO H enable
  [6] GPIOGLPEN — GPIO G enable
  [5] GPIOFLPEN — GPIO F enable
  [4] GPIOELPEN — GPIO E enable
  [3] GPIODLPEN — GPIO D enable
  [2] GPIOCLPEN — GPIO C enable
  [1] GPIOBLPEN — GPIO B enable
  [0] GPIOALPEN — GPIO A enable
0x2A0 AHB5LPENR — RCC AHB5 sleep enable register
  [31] NPULPEN — NPU enable
  [30] CACHEAXILPEN — CACHEAXI enable
  [29] OTG2LPEN — OTG2 enable
  [28] OTGPHY2LPEN — OTGPHY2 enable
  [27] OTGPHY1LPEN — OTGPHY1 enable
  [26] OTG1LPEN — OTG1 enable
  [25] ETH1LPEN — ETH1 enable
  [24] ETH1RXLPEN — ETH1RX enable
  [23] ETH1TXLPEN — ETH1TX enable
  [22] ETH1MACLPEN — ETH1MAC enable
  [20] GPU2DLPEN — GPU2D enable
  [19] GFXMMULPEN — GFXMMU enable
  [18] MCE4LPEN — MCE4 enable
  [17] XSPI3LPEN — XSPI3 enable
  [16] MCE3LPEN — MCE3 enable
  [15] MCE2LPEN — MCE2 enable
  [14] MCE1LPEN — MCE1 enable
  [13] XSPIMLPEN — XSPIM enable
  [12] XSPI2LPEN — XSPI2 enable
  [8] SDMMC1LPEN — SDMMC1 enable
  [7] SDMMC2LPEN — SDMMC2 enable
  [6] PSSILPEN — PSSI enable
  [5] XSPI1LPEN — XSPI1 enable
  [4] FMCLPEN — FMC enable
  [3] JPEGLPEN — JPEG enable
  [1] DMA2DLPEN — DMA2D enable
  [0] HPDMA1LPEN — HPDMA1 enable
0x2A4 APB1LPENR1 — RCC APB1 sleep enable register 1
  [31] UART8LPEN — UART8 enable
  [30] UART7LPEN — UART7 enable
  [25] I3C2LPEN — I3C2 enable
  [24] I3C1LPEN — I3C1 enable
  [23] I2C3LPEN — I2C3 enable
  [22] I2C2LPEN — I2C2 enable
  [21] I2C1LPEN — I2C1 enable
  [20] UART5LPEN — UART5 enable
  [19] UART4LPEN — UART4 enable
  [18] USART3LPEN — USART3 enable
  [17] USART2LPEN — USART2 enable
  [16] SPDIFRX1LPEN — SPDIFRX1 enable
  [15] SPI3LPEN — SPI3 enable
  [14] SPI2LPEN — SPI2 enable
  [13] TIM11LPEN — TIM11 enable
  [12] TIM10LPEN — TIM10 enable
  [11] WWDGLPEN — WWDG enable
  [9] LPTIM1LPEN — LPTIM1 enable
  [8] TIM14LPEN — TIM14 enable
  [7] TIM13LPEN — TIM13 enable
  [6] TIM12LPEN — TIM12 enable
  [n-2] TIM{n}LPEN (n=2..7) — TIM{n} enable
0x2A8 APB1LPENR2 — RCC APB1 sleep enable register 2
  [18] UCPD1LPEN — UCPD1 enable in Sleep mode
  [8] FDCANLPEN — FDCAN enablein Sleep mode
  [5] MDIOSLPEN — MDIOS enable in Sleep mode
0x2AC APB2LPENR — RCC APB2 sleep enable register
  [22] SAI2LPEN — SAI2 enable
  [21] SAI1LPEN — SAI1 enable
  [20] SPI5LPEN — SPI5 enable
  [19] TIM9LPEN — TIM9 enable
  [18] TIM17LPEN — TIM17 enable
  [17] TIM16LPEN — TIM16 enable
  [16] TIM15LPEN — TIM15 enable
  [15] TIM18LPEN — TIM18 enable
  [13] SPI4LPEN — SPI4 enable
  [12] SPI1LPEN — SPI1 enable
  [7] USART10LPEN — USART10 enable
  [6] UART9LPEN — UART9 enable
  [5] USART6LPEN — USART6 enable
  [4] USART1LPEN — USART1 enable
  [1] TIM8LPEN — TIM8 enable
  [0] TIM1LPEN — TIM1 enable
0x2B0 APB3LPENR — RCC APB3 sleep enable register
  [2] DFTLPEN — DFT enable
0x2B4 APB4LPENR1 — RCC APB4 sleep enable register 1
  [17] RTCAPBLPEN — RTCAPB enable
  [16] RTCLPEN — RTC enable
  [15] VREFBUFLPEN — VREFBUF enable
  [n+7] LPTIM{n}LPEN (n=2..5) — LPTIM{n} enable
  [7] I2C4LPEN — I2C4 enable
  [5] SPI6LPEN — SPI6 enable
  [3] LPUART1LPEN — LPUART1 enable
  [2] HDPLPEN — HDP enable
0x2B8 APB4LPENR2 — RCC APB4 sleep enable register 2
  [2] DTSLPEN — DTS enable
  [1] BSECLPEN — BSEC enable
  [0] SYSCFGLPEN — SYSCFG enable
0x2BC APB5LPENR — RCC APB5 sleep enable register
  [6] CSILPEN — CSI enable
  [5] VENCLPEN — VENC enable
  [4] GFXTIMLPEN — GFXTIM enable
  [2] DCMIPPLPEN — DCMIPP enable
  [1] LTDCLPEN — LTDC enable
0x44C RDCR — RCC reset duration control register
  [20:16] MRD — Minimum reset duration
0x780 SECCFGR0 — RCC oscillator secure configuration register 0
  [4] HSESEC — Secure protection of HSE oscillator configuration bits
  [3] HSISEC — Secure protection of HSI oscillator configuration bits
  [2] MSISEC — Secure protection of MSI oscillator configuration bits
  [1] LSESEC — Secure protection of LSE oscillator configuration bits
  [0] LSISEC — Secure protection of LSI oscillator configuration bits
0x784 PRIVCFGR0 — RCC oscillator privilege configuration register 0
  [4] HSEPRIV — Privileged protection of HSE oscillator configuration bits
  [3] HSIPRIV — Privileged protection of HSI oscillator configuration bits
  [2] MSIPRIV — Privileged protection of MSI oscillator configuration bits
  [1] LSEPRIV — Privileged protection of LSE oscillator configuration bits
  [0] LSIPRIV — Privileged protection of LSI oscillator configuration bits
0x788 LOCKCFGR0 — RCC oscillator lock configuration register 0
  [4] HSELOCK — Locked protection of HSE oscillator configuration bits
  [3] HSILOCK — Locked protection of HSI oscillator configuration bits
  [2] MSILOCK — Locked protection of MSI oscillator configuration bits
  [1] LSELOCK — Locked protection of LSE oscillator configuration bits
  [0] LSILOCK — Locked protection of LSI oscillator configuration bits
0x78C PUBCFGR0 — RCC oscillator public configuration register 0
  [4] HSEPUB — Public protection of HSE oscillator configuration bits
  [3] HSIPUB — Public protection of HSI oscillator configuration bits
  [2] MSIPUB — Public protection of MSI oscillator configuration bits
  [1] LSEPUB — Public protection of LSE oscillator configuration bits
  [0] LSIPUB — Public protection of LSI oscillator configuration bits
0x790 SECCFGR1 — RCC PLL secure configuration register 1
  [n-1] PLL{n}SEC (n=1..4) — Secure protection of PLL{n} configuration bits
0x794 PRIVCFGR1 — RCC PLL privilege configuration register 1
  [n-1] PLL{n}PRIV (n=1..4) — Privileged protection of PLL{n} configuration bits
0x798 LOCKCFGR1 — RCC PLL lock configuration register 1
  [n-1] PLL{n}LOCK (n=1..4) — Locked protection of PLL{n} configuration bits
0x79C PUBCFGR1 — RCC PLL public configuration register 1
  [n-1] PLL{n}PUB (n=1..4) — Public protection of PLL{n} configuration bits
0x7A0 SECCFGR2 — RCC divider secure configuration register 2
  [n-1] IC{n}SEC (n=1..20) — Secure protection of IC{n} divider configuration bits
0x7A4 PRIVCFGR2 — RCC divider privilege configuration register 2
  [19] IC20PRIV — Privileged protection of IC20 divider configuration bits
  [18] IC19PRIV — Privileged protection of IC19 divider configuration bits
  [17] IC18PRIV — Privilege protection of IC18 divider configuration bits
  [16] IC17PRIV — Privileges protection of IC17 divider configuration bits
  [n-1] IC{n}PRIV (n=1..16) — Privileged protection of IC{n} divider configuration bits
0x7A8 LOCKCFGR2 — RCC divider lock configuration register 2
  [n-1] IC{n}LOCK (n=1..20) — Locked protection of IC{n} divider configuration bits
0x7AC PUBCFGR2 — RCC divider public configuration register 2
  [n-1] IC{n}PUB (n=1..20) — Public protection of IC{n} divider configuration bits
0x7B0 SECCFGR3 — RCC system secure configuration register 3
  [5] RSTSEC — Secure protection of RST system configuration bits
  [4] INTSEC — Secure protection of INT system configuration bits
  [3] PERSEC — Secure protection of PER system configuration bits
  [2] BUSSEC — Secure protection of BUS system configuration bits
  [1] SYSSEC — Secure protection of SYS system configuration bit
  [0] MODSEC — Secure protection of MOD system configuration bits
0x7B4 PRIVCFGR3 — RCC system privilege configuration register 3
  [5] RSTPRIV — Privileged protection of RST system configuration bits
  [4] INTPRIV — Privileged protection of INT system configuration bits
  [3] PERPRIV — Privileged protection of PER system configuration bits
  [2] BUSPRIV — Privileged protection of BUS system configuration bits
  [1] SYSPRIV — Privileged protection of SYS system configuration bits
  [0] MODPRIV — Privileged protection of MOD system configuration bits
0x7B8 LOCKCFGR3 — RCC system lock configuration register 3
  [5] RSTLOCK — Locked protection of RST system configuration bits
  [4] INTLOCK — Locked protection of INT system configuration bits
  [3] PERLOCK — Locked protection of PER system configuration bits
  [2] BUSLOCK — Locked protection of BUS system configuration bits
  [1] SYSLOCK — Locked protection of SYS system configuration bits
  [0] MODLOCK — Locked protection of MOD system configuration bits
0x7BC PUBCFGR3 — RCC system public configuration register 3
  [5] RSTPUB — Public protection of RST system configuration bits
  [4] INTPUB — Public protection of INT system configuration bits
  [3] PERPUB — Public protection of PER system configuration bits
  [2] BUSPUB — Public protection of BUS system configuration bits
  [1] SYSPUB — Public protection of SYS system configuration bits
  [0] MODPUB — Public protection of MOD system configuration bits
0x7C0 SECCFGR4 — RCC bus secure configuration register 4
  [13] NOCSEC — Secure protection of NOC bus configuration bits
  [n+7] APB{n}SEC (n=1..5) — Secure protection of APB{n} bus configuration bits
  [n+2] AHB{n}SEC (n=1..5) — Secure protection of AHB{n} bus configuration bits
  [2] AHBMSEC — Secure protection of AHBM bus configuration bits
  [1] ACLKNCSEC — Secure protection of ACLKNC bus configuration bits
  [0] ACLKNSEC — Secure protection of ACLKN bus configuration bits
0x7C4 PRIVCFGR4 — RCC bus privilege configuration register 4
  [13] NOCPRIV — Privileged protection of NOC bus configuration bits
  [n+7] APB{n}PRIV (n=1..5) — Privileged protection of APB{n} bus configuration bits
  [n+2] AHB{n}PRIV (n=1..5) — Privileged protection of AHB{n} bus configuration bits
  [2] AHBMPRIV — Privileged protection of AHBM bus configuration bits
  [1] ACLKNCPRIV — Privileged protection of ACLKNC bus configuration bits
  [0] ACLKNPRIV — Privileged protection of ACLKN bus configuration bits
0x7C8 LOCKCFGR4 — RCC bus lock configuration register 4
  [13] NOCLOCK — Locked protection of NOC bus configuration bits
  [n+7] APB{n}LOCK (n=1..5) — Locked protection of APB{n} bus configuration bits
  [n+2] AHB{n}LOCK (n=1..5) — Locked protection of AHB{n} bus configuration bits
  [2] AHBMLOCK — Locked protection of AHBM bus configuration bits
  [1] ACLKNCLOCK — Locked protection of ACLKNC bus configuration bits
  [0] ACLKNLOCK — Locked protection of ACLKN bus configuration bits
0x7CC PUBCFGR4 — RCC bus public configuration register 4
  [13] NOCPUB — Public protection of NOC bus configuration bits
  [n+7] APB{n}PUB (n=1..5) — Public protection of APB{n} bus configuration bits
  [n+2] AHB{n}PUB (n=1..5) — Public protection of AHB{n} bus configuration bits
  [2] AHBMPUB — Public protection of AHBM bus configuration bits
  [1] ACLKNCPUB — Public protection of ACLKNC bus configuration bits
  [0] ACLKNPUB — Public protection of the ACLKN bus configuration bits
0x7D0 PUBCFGR5 — RCC bus public configuration register 4
  [11] VENCRAMPUB — Public protection of VENCRAM bus configuration bits
  [10] CACHEAXIRAMPUB — Public protection of CACHEAXIRAM bus configuration bits
  [9] FLEXRAMPUB — Public protection of FLEXRAM bus configuration bits
  [8] AXISRAM2PUB — Public protection of AXISRAM2 bus configuration bits
  [7] AXISRAM1PUB — Public protection of AXISRAM1 bus configuration bits
  [6] BKPSRAMPUB — Public protection of BKPSRAM bus configuration bits
  [5] AHBSRAM2PUB — Public protection of AHBSRAM2 bus configuration bits
  [4] AHBSRAM1PUB — Public protection of AHBSRAM1 bus configuration bits
  [n-3] AXISRAM{n}PUB (n=3..6) — Public protection of AXISRAM{n} bus configuration bits
0x800 CSR — RCC control Set register
  [n+7] PLL{n}ONS (n=1..4) — PLL{n} oscillator enable
  [4] HSEONS — HSE oscillator enable
  [3] HSIONS — HSI oscillator enable
  [2] MSIONS — MSI oscillator enable
  [1] LSEONS — LSE oscillator enable
  [0] LSIONS — LSI oscillator enable
0x808 STOPCSR — RCC STOPCSR configuration register
  [1] HSISTOPENS — HSI oscillator enable
  [0] MSISTOPENS — MSI oscillator enable
0xA08 MISCRSTSR — RCC miscellaneous reset register
  [8] SDMMC2DLLRSTS — SDMMC2DLL reset
  [7] SDMMC1DLLRSTS — SDMMC1DLL reset
  [5] XSPIPHY2RSTS — XSPIPHY2 reset
  [4] XSPIPHY1RSTS — XSPIPHY1 reset
  [0] DBGRSTS — DBG reset
0xA0C MEMRSTSR — RCC memory reset register
  [12] BOOTROMRSTS — Boot ROM reset
  [11] VENCRAMRSTS — VENCRAM reset
  [10] CACHEAXIRAMRSTS — CACHEAXIRAM reset
  [9] FLEXRAMRSTS — FLEXRAM reset
  [8] AXISRAM2RSTS — AXISRAM2 reset
  [7] AXISRAM1RSTS — AXISRAM1 reset
  [5] AHBSRAM2RSTS — AHBSRAM2 reset
  [4] AHBSRAM1RSTS — AHBSRAM1 reset
  [n-3] AXISRAM{n}RSTS (n=3..6) — AXISRAM{n} reset
0xA10 AHB1RSTSR — RCC AHB1 reset register
  [5] ADC12RSTS — ADC12 reset
  [4] GPDMA1RSTS — GPDMA1 reset
0xA14 AHB2RSTSR — RCC AHB2 reset register
  [17] ADF1RSTS — ADF1 reset
  [16] MDF1RSTS — MDF1 reset
  [12] RAMCFGRSTS — RAMCFG reset
0xA18 AHB3RSTSR — RCC AHB3 reset register
  [10] IACRSTS — IAC reset
  [8] PKARSTS — PKA reset
  [4] SAESRSTS — SAES reset
  [2] CRYPRSTS — CRYP reset
  [1] HASHRSTS — HASH reset
  [0] RNGRSTS — RNG reset
0xA1C AHB4RSTSR — RCC AHB4 reset register
  [19] CRCRSTS — CRC reset
  [18] PWRRSTS — PWR reset
  [16] GPIOQRSTS — GPIO Q reset
  [15] GPIOPRSTS — GPIO P reset
  [14] GPIOORSTS — GPIO O reset
  [13] GPIONRSTS — GPIO N reset
  [7] GPIOHRSTS — GPIO H reset
  [6] GPIOGRSTS — GPIO G reset
  [5] GPIOFRSTS — GPIO F reset
  [4] GPIOERSTS — GPIO E reset
  [3] GPIODRSTS — GPIO D reset
  [2] GPIOCRSTS — GPIO C reset
  [1] GPIOBRSTS — GPIO B reset
  [0] GPIOARSTS — GPIO A reset
0xA20 AHB5RSTSR — RCC AHB5 reset register
  [31] NPURSTS — NPU reset
  [30] CACHEAXIRSTS — CACHEAXI reset
  [29] OTG2RSTS — OTG2 reset
  [28] OTGPHY2RSTS — OTGPHY2 reset
  [27] OTGPHY1RSTS — OTGPHY1 reset
  [26] OTG1RSTS — OTG1 reset
  [25] ETH1RSTS — ETH1 reset
  [24] OTG2PHYCTLRSTS — OTG2PHYCTL reset
  [23] OTG1PHYCTLRSTS — OTG1PHYCTL reset
  [20] GPU2DRSTS — GPU2D reset
  [19] GFXMMURSTS — GFXMMU reset
  [17] XSPI3RSTS — XSPI3 reset
  [13] XSPIMRSTS — XSPIM reset
  [12] XSPI2RSTS — XSPI2 reset
  [8] SDMMC1RSTS — SDMMC1 reset
  [7] SDMMC2RSTS — SDMMC2 reset
  [6] PSSIRSTS — PSSI reset
  [5] XSPI1RSTS — XSPI1 reset
  [4] FMCRSTS — FMC reset
  [3] JPEGRSTS — JPEG reset
  [1] DMA2DRSTS — DMA2D reset
  [0] HPDMA1RSTS — HPDMA1 reset
